# STM32F031C4T6 register map
File version: 1.0
Registers are 32-bit, access not given, reset 0x0 unless marked. A register's access mark holds for its fields unless they carry their own. Offsets are from the block's base; [hi:lo] are bit positions; {n}, {i} and the like mark numbered series; 'fields as' and 'values as' point back to an identical list.

## RTC
Base 0x40002800
0x00 TR
  [22] PM, [21:20] HT, [19:16] HU, [14:12] MNT, [11:8] MNU, [31:7] s, [6:4] ST, [3:0] SU
0x04 DR
  [23:20] YT, [19:16] YU, [15:13] WDU, [12] MT, [11:8] MU, [31:6] s, [5:4] DT, [3:0] DU
0x08 CR
  [23] COE, [22:21] OSEL, [20] POL, [19] COSEL, [18] BKP, [17] SUB1H, [16] ADD1H, [15] TSIE, [14] WUTIE, [12] ALRAIE, [11] TSE, [10] WUTE, [8] ALRAE, [31:7] s, [6] FMT, [5] BYPSHAD, [4] REFCKON, [3] TSEDGE, [2:0] WUCKSEL
0x0C ISR
  [16] RECALPF, [15] TAMP3F, [14] TAMP2F, [13] TAMP1F, [12] TSOVF, [11] TSF, [10] WUTF, [8] ALRAF, [7] INIT, [6] INITF, [5] RSF, [4] INITS, [3] SHPF, [2] WUTWF, [31:1] s, [0] ALRAWF
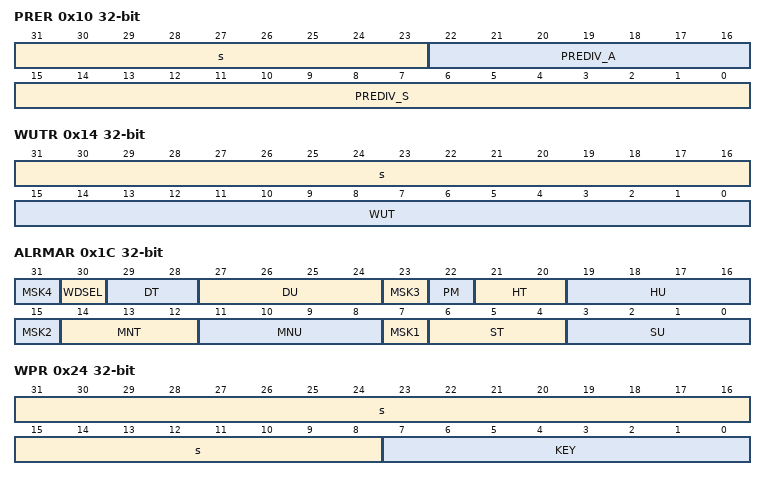
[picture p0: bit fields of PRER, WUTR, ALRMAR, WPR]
0x10 PRER
  [31:23] s, [22:16] PREDIV_A, [15:0] PREDIV_S
0x14 WUTR
  [31:16] s, [15:0] WUT
0x1C ALRMAR
  [8n-1] MSK{n} (n=1..4), [30] WDSEL, [29:28] DT, [27:24] DU, [22] PM, [21:20] HT, [19:16] HU, [14:12] MNT, [11:8] MNU, [6:4] ST, [3:0] SU
0x24 WPR
  [31:8] s, [7:0] KEY
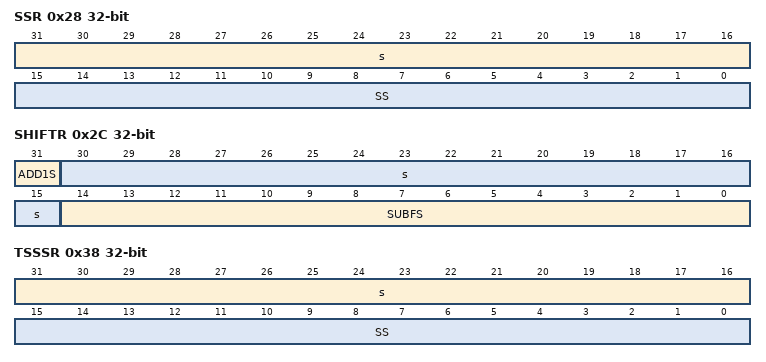
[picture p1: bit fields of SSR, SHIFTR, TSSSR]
0x28 SSR
  [31:16] s, [15:0] SS
0x2C SHIFTR
  [31] ADD1S, [30:15] s, [14:0] SUBFS
0x30 TSTR
  fields as TR
0x34 TSDR
  [15:13] WDU, [12] MT, [11:8] MU, [31:6] s, [5:4] DT, [3:0] DU
0x38 TSSSR
  [31:16] s, [15:0] SS
0x3C CALR
  [15] CALP, [14] CALW8, [13] CALW16, [31:9] s, [8:0] CALM
0x40 TAFCR
  [23:22] PC15MODE, [21] PC14VALUE, [20] PC14MODE, [19:18] PC13VALUE, [31:16] s, [15] TAMPPUDIS, [14:13] TAMPPRCH, [12:11] TAMPFLT, [10:8] TAMPFREQ, [7] TAMPTS, [6] TAMP3TRG, [5] TAMP3E, [4] TAMP2TRG, [3] TAMP2E, [2] TAMPIE, [1] TAMP1TRG, [0] TAMP1E
0x44 ALRMASSR
  [27:24] MASKSS, [31:15] s, [14:0] SS
{0x50+4i} BKP{i}R (i=0..4)
  [31:0] BKP

## WWDG
Base 0x40002C00
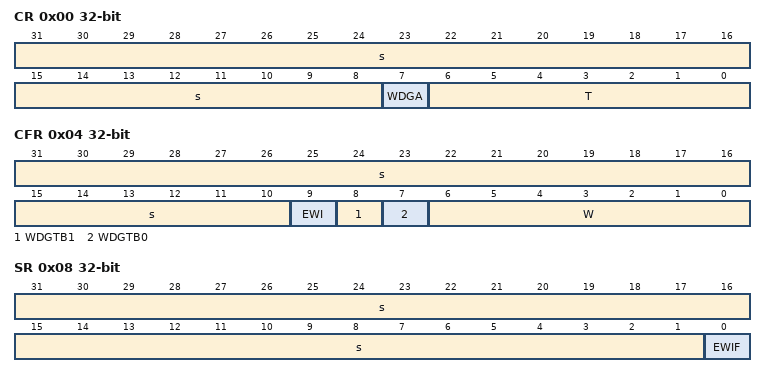
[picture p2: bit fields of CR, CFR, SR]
0x00 CR
  [31:8] s, [7] WDGA, [6:0] T
0x04 CFR
  [31:10] s, [9] EWI, [8] WDGTB1, [7] WDGTB0, [6:0] W
0x08 SR
  [31:1] s, [0] EWIF

## IWDG
Base 0x40003000
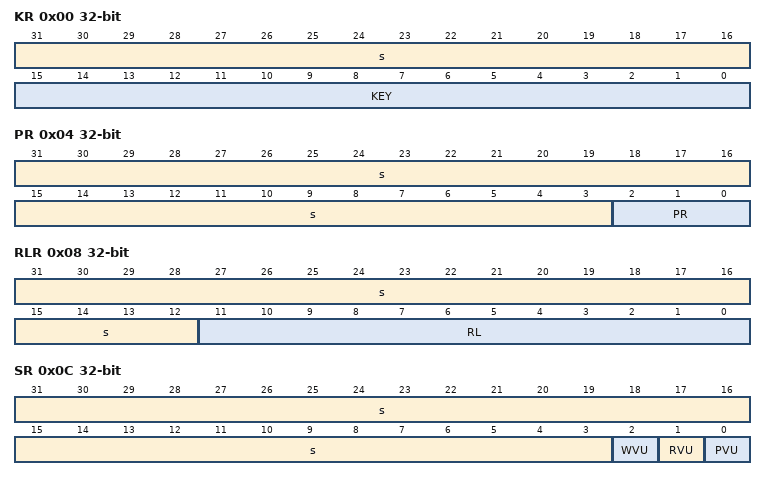
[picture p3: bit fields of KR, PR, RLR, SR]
0x00 KR
  [31:16] s, [15:0] KEY
0x04 PR
  [31:3] s, [2:0] PR
0x08 RLR
  [31:12] s, [11:0] RL
0x0C SR
  [31:3] s, [2] WVU, [1] RVU, [0] PVU
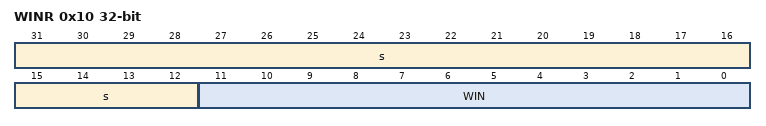
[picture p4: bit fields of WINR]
0x10 WINR
  [31:12] s, [11:0] WIN

## SPI2
Base 0x40003800
Same registers: SPI1 0x40013000
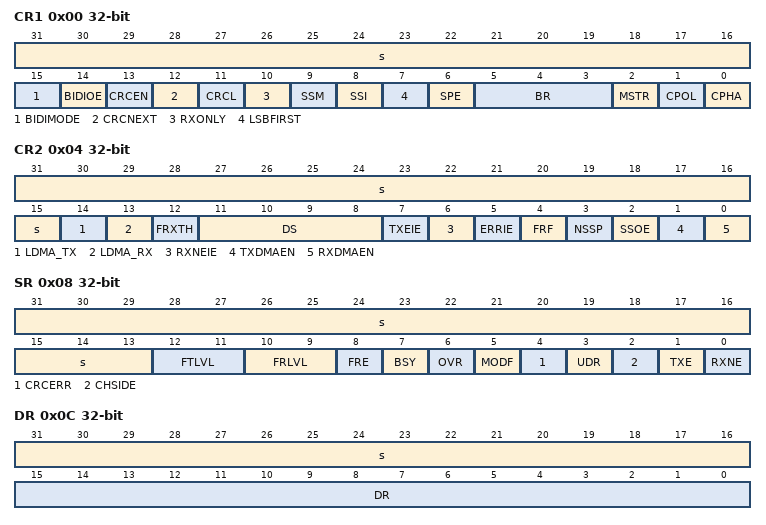
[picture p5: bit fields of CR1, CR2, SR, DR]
0x00 CR1
  [31:16] s, [15] BIDIMODE, [14] BIDIOE, [13] CRCEN, [12] CRCNEXT, [11] CRCL, [10] RXONLY, [9] SSM, [8] SSI, [7] LSBFIRST, [6] SPE, [5:3] BR, [2] MSTR, [1] CPOL, [0] CPHA
0x04 CR2
  [31:15] s, [14] LDMA_TX, [13] LDMA_RX, [12] FRXTH, [11:8] DS, [7] TXEIE, [6] RXNEIE, [5] ERRIE, [4] FRF, [3] NSSP, [2] SSOE, [1] TXDMAEN, [0] RXDMAEN
0x08 SR
  [31:13] s, [12:11] FTLVL, [10:9] FRLVL, [8] FRE, [7] BSY, [6] OVR, [5] MODF, [4] CRCERR, [3] UDR, [2] CHSIDE, [1] TXE, [0] RXNE
0x0C DR
  [31:16] s, [15:0] DR
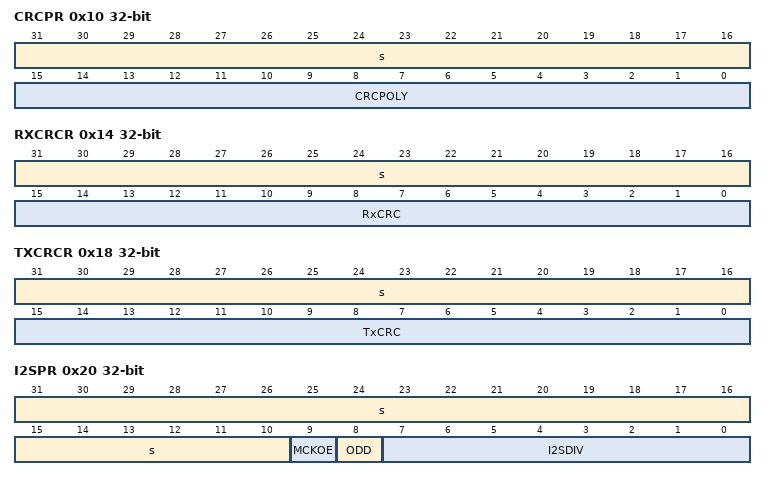
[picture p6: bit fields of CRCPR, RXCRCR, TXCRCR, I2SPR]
0x10 CRCPR
  [31:16] s, [15:0] CRCPOLY
0x14 RXCRCR
  [31:16] s, [15:0] RxCRC
0x18 TXCRCR
  [31:16] s, [15:0] TxCRC
0x1C I2SCFGR
  [11] I2SMOD, [10] I2SE, [9:8] I2SCFG, [7] PCMSYNC, [31:6] s, [5:4] I2SSTD, [3] CKPOL, [2:1] DATLEN, [0] CHLEN
0x20 I2SPR
  [31:10] s, [9] MCKOE, [8] ODD, [7:0] I2SDIV

## USART2
Base 0x40004400
Same registers: USART3 0x40004800, USART4 0x40004C00, USART5 0x40005000, USART6 0x40011400, USART7 0x40011800, USART8 0x40011C00, USART1 0x40013800
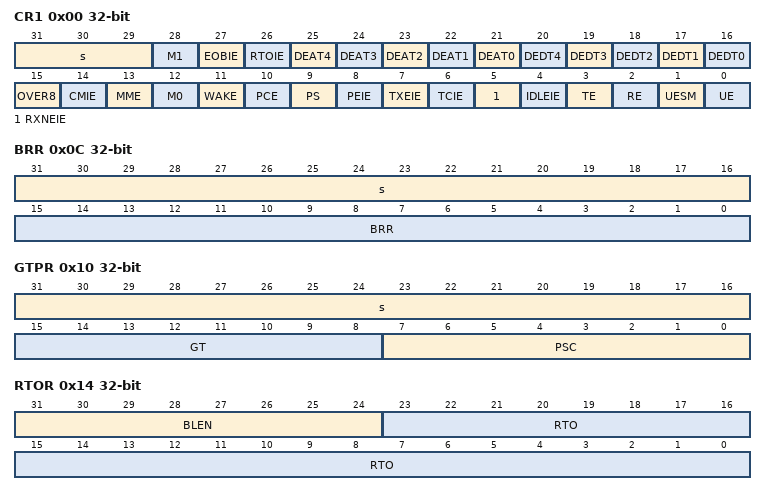
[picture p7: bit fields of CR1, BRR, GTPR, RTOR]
0x00 CR1
  [31:29] s, [28] M1, [27] EOBIE, [26] RTOIE, [n+21] DEAT{n} (n=0..4), [n+16] DEDT{n} (n=0..4), [15] OVER8, [14] CMIE, [13] MME, [12] M0, [11] WAKE, [10] PCE, [9] PS, [8] PEIE, [7] TXEIE, [6] TCIE, [5] RXNEIE, [4] IDLEIE, [3] TE, [2] RE, [1] UESM, [0] UE
0x04 CR2
  [31:24] ADD, [23] RTOEN, [22] ABRMOD1, [21] ABRMOD0, [20] ABREN, [19] MSBFIRST, [18] DATAINV, [17] TXINV, [16] RXINV, [15] SWAP, [14] LINEN, [13:12] STOP, [11] CLKEN, [10] CPOL, [9] CPHA, [8] LBCL, [6] LBDIE, [5] LBDL, [4] ADDM7, [7:0] s
0x08 CR3
  [22] WUFIE, [21:20] WUS, [19:17] SCARCNT, [31:16] s, [15] DEP, [14] DEM, [13] DDRE, [12] OVRDIS, [11] ONEBIT, [10] CTSIE, [9] CTSE, [8] RTSE, [7] DMAT, [6] DMAR, [5] SCEN, [4] NACK, [3] HDSEL, [2] IRLP, [1] IREN, [0] EIE
0x0C BRR
  [31:16] s, [15:0] BRR
0x10 GTPR
  [31:16] s, [15:8] GT, [7:0] PSC
0x14 RTOR
  [31:24] BLEN, [23:0] RTO
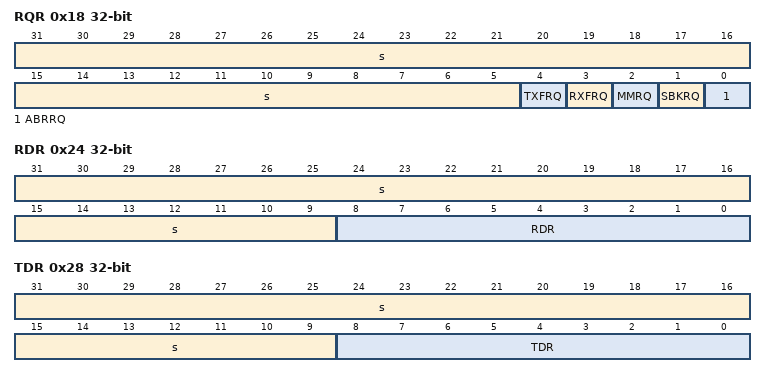
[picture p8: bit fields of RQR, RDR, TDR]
0x18 RQR
  [31:5] s, [4] TXFRQ, [3] RXFRQ, [2] MMRQ, [1] SBKRQ, [0] ABRRQ
0x1C ISR
  [22] REACK, [21] TEACK, [20] WUF, [19] RWU, [18] SBKF, [17] CMF, [16] BUSY, [15] ABRF, [14] ABRE, [31:13] s, [12] EOBF, [11] RTOF, [10] CTS, [9] CTSIF, [8] LBDF, [7] TXE, [6] TC, [5] RXNE, [4] IDLE, [3] ORE, [2] NF, [1] FE, [0] PE
0x20 ICR
  [20] WUCF, [17] CMCF, [12] EOBCF, [11] RTOCF, [9] CTSCF, [8] LBDCF, [6] TCCF, [31:5] s, [4] IDLECF, [3] ORECF, [2] NCF, [1] FECF, [0] PECF
0x24 RDR
  [31:9] s, [8:0] RDR
0x28 TDR
  [31:9] s, [8:0] TDR
